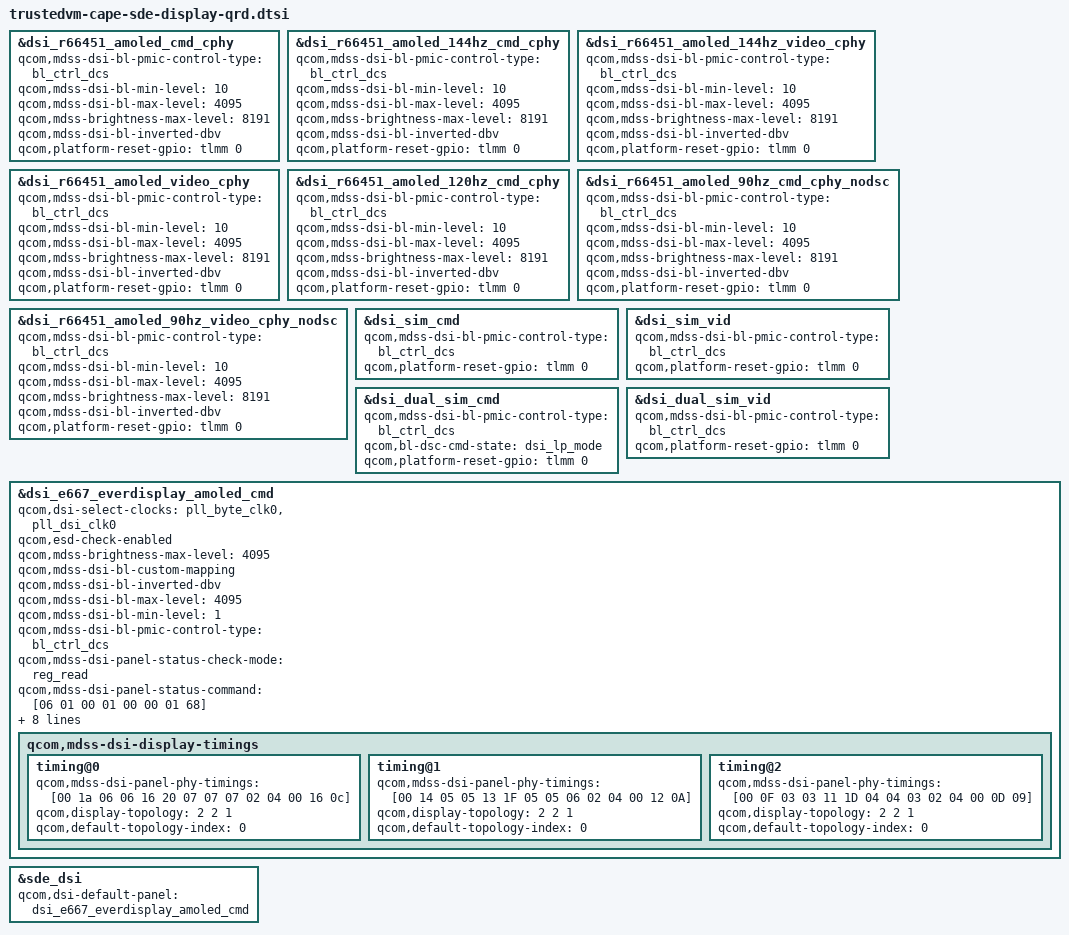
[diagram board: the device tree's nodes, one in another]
#include "trustedvm-cape-sde-display.dtsi"

&dsi_r66451_amoled_cmd_cphy {
	qcom,mdss-dsi-bl-pmic-control-type = "bl_ctrl_dcs";
	qcom,mdss-dsi-bl-min-level = <10>;
	qcom,mdss-dsi-bl-max-level = <4095>;
	qcom,mdss-brightness-max-level = <8191>;
	qcom,mdss-dsi-bl-inverted-dbv;
	qcom,platform-reset-gpio = <&tlmm 0 0>;
};

&dsi_r66451_amoled_144hz_cmd_cphy {
	qcom,mdss-dsi-bl-pmic-control-type = "bl_ctrl_dcs";
	qcom,mdss-dsi-bl-min-level = <10>;
	qcom,mdss-dsi-bl-max-level = <4095>;
	qcom,mdss-brightness-max-level = <8191>;
	qcom,mdss-dsi-bl-inverted-dbv;
	qcom,platform-reset-gpio = <&tlmm 0 0>;
};

&dsi_r66451_amoled_144hz_video_cphy {
	qcom,mdss-dsi-bl-pmic-control-type = "bl_ctrl_dcs";
	qcom,mdss-dsi-bl-min-level = <10>;
	qcom,mdss-dsi-bl-max-level = <4095>;
	qcom,mdss-brightness-max-level = <8191>;
	qcom,mdss-dsi-bl-inverted-dbv;
	qcom,platform-reset-gpio = <&tlmm 0 0>;
};

&dsi_r66451_amoled_video_cphy {
	qcom,mdss-dsi-bl-pmic-control-type = "bl_ctrl_dcs";
	qcom,mdss-dsi-bl-min-level = <10>;
	qcom,mdss-dsi-bl-max-level = <4095>;
	qcom,mdss-brightness-max-level = <8191>;
	qcom,mdss-dsi-bl-inverted-dbv;
	qcom,platform-reset-gpio = <&tlmm 0 0>;
};

&dsi_r66451_amoled_120hz_cmd_cphy {
	qcom,mdss-dsi-bl-pmic-control-type = "bl_ctrl_dcs";
	qcom,mdss-dsi-bl-min-level = <10>;
	qcom,mdss-dsi-bl-max-level = <4095>;
	qcom,mdss-brightness-max-level = <8191>;
	qcom,mdss-dsi-bl-inverted-dbv;
	qcom,platform-reset-gpio = <&tlmm 0 0>;
};

&dsi_r66451_amoled_90hz_cmd_cphy_nodsc {
	qcom,mdss-dsi-bl-pmic-control-type = "bl_ctrl_dcs";
	qcom,mdss-dsi-bl-min-level = <10>;
	qcom,mdss-dsi-bl-max-level = <4095>;
	qcom,mdss-brightness-max-level = <8191>;
	qcom,mdss-dsi-bl-inverted-dbv;
	qcom,platform-reset-gpio = <&tlmm 0 0>;
};

&dsi_r66451_amoled_90hz_video_cphy_nodsc {
	qcom,mdss-dsi-bl-pmic-control-type = "bl_ctrl_dcs";
	qcom,mdss-dsi-bl-min-level = <10>;
	qcom,mdss-dsi-bl-max-level = <4095>;
	qcom,mdss-brightness-max-level = <8191>;
	qcom,mdss-dsi-bl-inverted-dbv;
	qcom,platform-reset-gpio = <&tlmm 0 0>;
};

&dsi_sim_cmd {
	qcom,mdss-dsi-bl-pmic-control-type = "bl_ctrl_dcs";
	qcom,platform-reset-gpio = <&tlmm 0 0>;
};

&dsi_sim_vid {
	qcom,mdss-dsi-bl-pmic-control-type = "bl_ctrl_dcs";
	qcom,platform-reset-gpio = <&tlmm 0 0>;
};

&dsi_dual_sim_cmd {
	qcom,mdss-dsi-bl-pmic-control-type = "bl_ctrl_dcs";
	qcom,bl-dsc-cmd-state = "dsi_lp_mode";
	qcom,platform-reset-gpio = <&tlmm 0 0>;
};

&dsi_dual_sim_vid {
	qcom,mdss-dsi-bl-pmic-control-type = "bl_ctrl_dcs";
	qcom,platform-reset-gpio = <&tlmm 0 0>;
};

&dsi_e667_everdisplay_amoled_cmd {
	qcom,dsi-select-clocks = "pll_byte_clk0", "pll_dsi_clk0";
	qcom,esd-check-enabled;
	qcom,mdss-brightness-max-level = <4095>;
	qcom,mdss-dsi-bl-custom-mapping;
	qcom,mdss-dsi-bl-inverted-dbv;
	qcom,mdss-dsi-bl-max-level = <4095>;
	qcom,mdss-dsi-bl-min-level = <1>;
	qcom,mdss-dsi-bl-pmic-control-type = "bl_ctrl_dcs";
	qcom,mdss-dsi-panel-status-check-mode = "reg_read";
	qcom,mdss-dsi-panel-status-command = [06 01 00 01 00 00 01 68];
	qcom,mdss-dsi-panel-status-command-state = "dsi_lp_mode";
	qcom,mdss-dsi-panel-status-read-length = <1>;
	qcom,mdss-dsi-panel-status-value = <0x00>;
	qcom,panel-supply-entries = <&dsi_panel_pwr_supply>;
	qcom,platform-reset-gpio = <&tlmm 0 0>;
	qcom,ulps-enabled;

	qcom,mdss-dsi-display-timings {
		timing@0 {
			qcom,mdss-dsi-panel-phy-timings = [00 1a 06 06 16 20 07 /*120HZ*/
				07 07 02 04 00 16 0c];
			qcom,display-topology = <2 2 1>;
			qcom,default-topology-index = <0>;
		};

		timing@1 {
			qcom,mdss-dsi-panel-phy-timings = [00 14 05 05 13 1F 05 /*90HZ*/
				05 06 02 04 00 12 0A];
			qcom,display-topology = <2 2 1>;
			qcom,default-topology-index = <0>;
		};

		timing@2 {
			qcom,mdss-dsi-panel-phy-timings = [00 0F 03 03 11 1D 04 /*60HZ*/
				04 03 02 04 00 0D 09];
			qcom,display-topology = <2 2 1>;
			qcom,default-topology-index = <0>;
		};
	};
};

&sde_dsi {
	qcom,dsi-default-panel = <&dsi_e667_everdisplay_amoled_cmd>;
};
